# SYSCTRL_ICONT register map
Vendor: Texas Instruments
Peripheral module from a debugger description file (folder omap5430_ES2_PUBLIC).
Registers are 32-bit, access per field, reset 0x0 unless marked. A register's access mark holds for its fields unless they carry their own. Offsets are as the file gives them; lines under a group give offsets from that group; [hi:lo] are bit positions; {n}, {i} and the like mark numbered series; 'fields as' and 'values as' point back to an identical list; <NAME> marks a mode.

## SYSCTRL_ICONT
0x00 IVAHD_REVISION ro reset not defined — IP revision identifier (X.Y.R). Used by software to track features, bugs, and compatibility
  [31:0] REVISION — IP revision
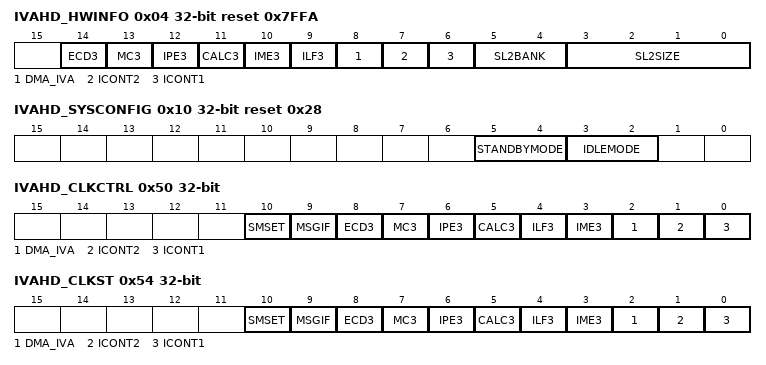
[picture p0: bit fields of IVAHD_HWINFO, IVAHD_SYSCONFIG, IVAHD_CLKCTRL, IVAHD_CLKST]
0x04 IVAHD_HWINFO ro reset 0x7FFA — Information about the IP module's hardware configuration.
  [14] ECD3 — ECD3 available 0: ECD3 not present 1: ECD3 present
  [13] MC3 — MC3 available 0: MC3 not present 1: MC3 present
  [12] IPE3 — IPE3 available 0: IPE3 not present 1: IPE3 present
  [11] CALC3 — CALC3 available 0: CALC3 not present 1: CALC3 present
  [10] IME3 — IME3 available 0: IME3 not present 1: IME3 present
  [9] ILF3 — ILF3 available 0: ILF3 not present 1: ILF3 present
  [8] DMA_IVA — DMA_IVA available 0: DMA_IVA not present 1: DMA_IVA present
  [7] ICONT2 — ICONT2 available 0: ICONT2 not present 1: ICONT2 present
  [6] ICONT1 — ICONT1 available 0: ICONT1 not present 1: ICONT1 present
  [5:4] SL2BANK
    0=1bank (1 memory bank); 1=2bank (2 memory bank); 2=4bank (4 memory bank); 3=8bank (8 memory bank)
  [3:0] SL2SIZE — Size of SL2 memory
    1=16kB (16 KiB); 2=32kB (32 KiB); 3=48kB (48 KiB); 4=64kB (64 KiB); 5=96kB (96 KiB); 6=128kB (128 KiB); 7=160kB (160 KiB); 8=192kB (192 KiB); 9=224kB (224 KiB); 10=256_KiB; 11=320_KiB; 12=384_KiB; 13=448_KiB; 14=512_KiB
0x10 IVAHD_SYSCONFIG reset 0x28 — Clock management configuration
  [5:4] STANDBYMODE rw — Configuration of the local initiator state management mode. By definition, initiator may generate read/write transaction as long as it is out of STANDBY state.0x0 and 0x3: Reserved enum=reserved1 .
    1=no (No-standby mode: local initiator is unconditionally placed out of standby state. Backup mode, for debug only.); 2=Smart-standby mode: local initiator standby status depends on local conditions, that is, the module's functional requirement from the initiator. IP module shall not generate (initiator-related) wakeup events.
  [3:2] IDLEMODE rw — Configuration of the local target state management mode. By definition, target can handle read/write transaction as long as it is out of IDLE state.0x0 and 0x3: Reserved enum=reserved1 .
    1=no (No-idle mode: local target never enters idle state. Backup mode, for debug only.); 2=Smart-idle mode: local target's idle state eventually follows (acknowledges) the system's idle requests, depending on the IP module's internal requirements. IP module shall not generate (IRQ- or DMA-request-related) wakeup events.
0x24 IVAHD_IRQSTATUS_RAW — Per-event raw interrupt status vector. Raw status is set even if event is not enabled. Write 1 to set the (raw) status, mostly for debug.
  [0] SYSCTRL_CLKERR rw — Settable raw status for Clock Programming Error event
    0=noevent (No action); 0=pending (No event pending); 1=set (Event pending); 1=Set_event_(debug)
0x28 IVAHD_IRQSTATUS — Per-event 'enabled' interrupt status vector, line 0. Enabled status is not set unless event is enabled. Write 1 to clear the status after interrupt has been serviced (raw status gets cleared, that is, even if not enabled).
  [0] SYSCTRL_CLKERR rw — Clearable, enabled status for Clock Programming Error event
    0=noevent (No action); 0=pending (No (enabled) event pending); 1=clear (Event pending); 1=Clear_(raw)_event
0x2C IVAHD_IRQENABLE_SET access not given — Per-event interrupt enable bit vector. Write 1 to set (enable interrupt). Readout equal to corresponding _CLR register.
  [0] SYSCTRL_CLKERR — Clock Programing Error (access RW W1toSet)
    0=disabled (No action); 0=Interrupt_disabled_(masked); 1=enabled (Interrupt enabled); 1=Enable_interrupt
0x30 IVAHD_IRQENABLE_CLR — Per-event interrupt enable bit vector. Write 1 to clear (disable interrupt). Readout equal to corresponding _SET register.
  [0] SYSCTRL_CLKERR rw — Clock Programing Error
    0=disabled (No action); 0=Interrupt_disabled_(masked); 1=enabled (Interrupt enabled); 1=Disable_interrupt
0x34 IVAHD_SYNC_IRQSTATUS_RAW — Per-event raw interrupt status vector. Raw status is set even if event is not enabled. Write 1 to set the (raw) status, mostly for debug.
  [7:0] SYNC_INPUT7_0 rw — Settable raw status for SYNC INPUT event. For each bit of the bit field: Read 0: No event pending Read 1: Event pending Write 0: No action Write 1: Set event (debug)
0x38 IVAHD_SYNC_IRQSTATUS — Per-event 'enabled' interrupt status vector, line 0. Enabled status is not set unless event is enabled. Write 1 to clear the status after interrupt has been serviced (raw status gets cleared, that is, even if not enabled).
  [7:0] SYNC_INPUT7_0 rw — Clearable, enabled status for SYNC INPUT event. For each bit of the bit field: Read 0: No (enabled) event pending Read 1: Event pending Write 0: No action Write 1: Clear (raw) event
0x3C IVAHD_SYNC_IRQENABLE_SET — Per-event interrupt enable bit vector. Write 1 to set (enable interrupt). Readout equal to corresponding _CLR register.
  [7:0] SYNC_INPUT7_0 rw — Enable for interrupt event. For each bit of the bit field: Read 0: Interrupt disabled (masked) Read 1: Interrupt enabled Write 0: No action Write 1: Enable interrupt
0x40 IVAHD_SYNC_IRQENABLE_CLR — Per-event interrupt enable bit vector. Write 1 to clear (disable interrupt). Readout equal to corresponding _SET register.
  [7:0] SYNC_INPUT7_0 rw — Enable for interrupt event. For each bit of the bitfiled: Read 0: Interrupt disabled (masked) Read 1: Interrupt enabled Write 0: No action Write 1: Disable interrupt
0x50 IVAHD_CLKCTRL — IVA clock control register
  [10] SMSET rw — Clock control of SMSET 0: Exit idle state and start SMSET clock 1: Request SMSET to go to idle state and stop SMSET clock Note: Shutting down SMSET clock may hang system if software performs software instrumentation and/or access to its configuration port.
  [9] MSGIF rw — Clock control of MSGIF 0: Exit idle state and start MSGIF clock 1: Request MSGIF to go to idle state and stop MSGIF clock
  [8] ECD3 rw — Clock control of ECD3 0: Exit idle state and start ECD3 clock 1: Request ECD3 to go to idle state and stop ECD3 clock
  [7] MC3 rw — Clock control of MC3 0: Exit idle state and start MC3 clock 1: Request MC3 to go to idle state and stop MC3 clock
  [6] IPE3 rw — Clock control of IPE3 0: Exit idle state and start IPE3 clock 1: Request IME3 to go to idle state and stop IPE3 clock
  [5] CALC3 rw — Clock control of CALC3 0: Exit idle state and start CALC3 clock 1: Request CALC3 to go to idle state and stop CALC3 clock
  [4] ILF3 rw — Clock control of ILF3 0: Exit idle state and start ILF3 clock 1: Request ILF3 to go to idle state and stop ILF3 clock
  [3] IME3 rw — Clock control of IME3 0: Exit idle state and start IME3 clock 1: Request IME3 to go to idle state and stop IME3 clock
  [2] DMA_IVA rw — Clock control of DMA_IVA 0: Exit idle state and start DMA_IVA clock 1: Request DMA_IVA to go to idle state and stop DMA_IVA clock
  [1] ICONT2 rw — Clock control of ICONT2 0: Exit idle state and start ICONT2 clock 1: Request ICONT2 to go to idle state and stop ICONT2 clock
  [0] ICONT1 rw — Clock control of ICONT1 0: Exit idle state and start ICONT1 clock 1: Request ICONT1 to go to idle state and stop ICONT1 clock
0x54 IVAHD_CLKST ro — IVA clock status register
  [10] SMSET — Clock status of SMSET 1: SMSET clock is active 0: SMSET clock is idled
  [9] MSGIF — Clock status of MSGIF 1: MSGIF clock is active 0: MSGIF clock is idled
  [8] ECD3 — Clock status of ECD3 1: ECD3 clock is active 0: ECD3 clock is idled
  [7] MC3 — Clock status of MC3 1: MC3 clock is active 0: MC3 clock is idled
  [6] IPE3 — Clock status of IPE3 1: IPE3 clock is active 0: IPE3 clock is idled
  [5] CALC3 — Clock status of CALC3 1: CALC3 clock is active 0: CALC3 clock is idled
  [4] ILF3 — Clock status of ILF3 1: ILF3 clock is active 0: ILF3 clock is idled
  [3] IME3 — Clock status of IME3 1: IME3 clock is active 0: IME3 clock is idled
  [2] DMA_IVA — Clock status of DMA_IVA 1: DMA_IVA clock is active 0: DMA_IVA clock is idled
  [1] ICONT2 — Clock status of ICONT2 1: ICONT2 clock is active 0: ICONT2 clock is idled
  [0] ICONT1 — Clock status of ICONT1 1: ICONT1 clock is active 0: ICONT1 clock is idled
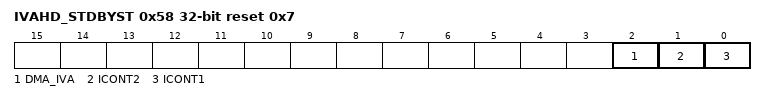
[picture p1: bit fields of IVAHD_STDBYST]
0x58 IVAHD_STDBYST ro reset 0x7 — IVA STANDBY status
  [2] DMA_IVA — DMA_IVA Standby status 0: module is not in Standby 1: module is in Standby
  [1] ICONT2 — ICONT2 Standby status 0: module is not in Standby 1: module is in Standby
  [0] ICONT1 — ICONT1 Standby status 0: module is not in Standby 1: module is in Standby
